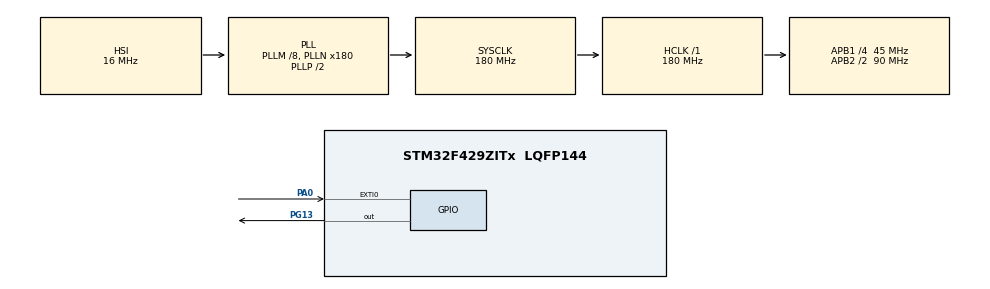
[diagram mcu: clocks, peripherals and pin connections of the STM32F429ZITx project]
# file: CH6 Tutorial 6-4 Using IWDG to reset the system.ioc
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IWDG.Prescaler=IWDG_PRESCALER_32
IWDG.Reload=4000-1
Mcu.Family=STM32F4
Mcu.Name=STM32F429ZITx
Mcu.Package=LQFP144
NVIC.EXTI0_IRQn=true\:1\:0\:true\:false\:true\:true\:true\:true
NVIC.PriorityGroup=NVIC_PRIORITYGROUP_1
NVIC.TIM1_UP_TIM10_IRQn=true\:1\:0\:true\:false\:true\:true\:true\:true
PA0/WKUP.GPIO_ModeDefaultEXTI=GPIO_MODE_IT_RISING
PA0/WKUP.Signal=GPXTI0
PG13.Signal=GPIO_Output
ProjectManager.HeapSize=0x200
ProjectManager.StackSize=0x400
ProjectManager.TargetToolchain=STM32CubeIDE
RCC.48MHZClocksFreq_Value=51428571.428571425
RCC.AHBFreq_Value=180000000
RCC.APB1CLKDivider=RCC_HCLK_DIV4
RCC.APB1Freq_Value=45000000
RCC.APB1TimFreq_Value=90000000
RCC.APB2CLKDivider=RCC_HCLK_DIV2
RCC.APB2Freq_Value=90000000
RCC.APB2TimFreq_Value=180000000
RCC.CortexFreq_Value=180000000
RCC.HCLKFreq_Value=180000000
RCC.HSE_VALUE=8000000
RCC.HSI_VALUE=16000000
RCC.LSE_VALUE=32768
RCC.PLLM=8
RCC.PLLN=180
RCC.PLLQ=7
RCC.SYSCLKFreq_VALUE=180000000
RCC.SYSCLKSource=RCC_SYSCLKSOURCE_PLLCLK
RCC.VCOOutputFreq_Value=360000000
TIM1.Period=50000-1
TIM1.Prescaler=3600-1
VP_IWDG_VS_IWDG.Mode=IWDG_Activate
VP_TIM1_VS_ClockSourceINT.Mode=Internal
board=STM32F429I-DISC1

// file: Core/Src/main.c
/* USER CODE BEGIN Header */
/**
  ******************************************************************************
  * @file           : main.c
  * @brief          : Main program body
  ******************************************************************************
  * @attention
  *
  * Copyright (c) 2023 STMicroelectronics.
  * All rights reserved.
  *
  * This software is licensed under terms that can be found in the LICENSE file
  * in the root directory of this software component.
  * If no LICENSE file comes with this software, it is provided AS-IS.
  *
  ******************************************************************************
  */
	/***************************** Tutorial Tags ******************************
	 Independent Watchdog (IWDG)Timer
	 GPIO Digital output
	 GPIO Interrupt
	 **************************************************************************/

	/* 6.4.1 Timer Usage C Language: ******************************************
	* Tutorial 6-4: Using IWDG to reset the system, in C language
	*

    Use the IWDG to reset the CPU when the code goes into an infinite loop

	So, in this tutorial we toggle the green led every 1s using timer interrupt.
	We also set IWDG to start with 4s timeout. The IWDG is refreshed every time
	the green led is toggled. When the user button is pressed, a GPIO interrupt is
	generated and the code goes into an infinite loop. After 4 seconds lapses, IWDG
	resets CPU and the code goes back to toggling the green led.
	***************************************************************************/
/* USER CODE END Header */
#include "main.h"

IWDG_HandleTypeDef hiwdg;

TIM_HandleTypeDef htim1;

void SystemClock_Config(void);
static void MX_GPIO_Init(void);
static void MX_IWDG_Init(void);
static void MX_TIM1_Init(void);

int main(void)
{

  /* MCU Configuration--------------------------------------------------------*/

  /* Reset of all peripherals, Initializes the Flash interface and the Systick. */
  HAL_Init();

  /* Configure the system clock */
  SystemClock_Config();

  /* Initialize all configured peripherals */
  MX_GPIO_Init();
  MX_IWDG_Init();
  MX_TIM1_Init();
  /* USER CODE BEGIN 2 */
  HAL_TIM_Base_Start_IT(&htim1);

  /* USER CODE END 2 */

  /* Infinite loop */
  while (1)
  {

  }
}

void SystemClock_Config(void)
{
  RCC_OscInitTypeDef RCC_OscInitStruct = {0};
  RCC_ClkInitTypeDef RCC_ClkInitStruct = {0};

  /** Configure the main internal regulator output voltage
  */
  __HAL_RCC_PWR_CLK_ENABLE();
  __HAL_PWR_VOLTAGESCALING_CONFIG(PWR_REGULATOR_VOLTAGE_SCALE1);

  /** Initializes the RCC Oscillators according to the specified parameters
  * in the RCC_OscInitTypeDef structure.
  */
  RCC_OscInitStruct.OscillatorType = RCC_OSCILLATORTYPE_HSI|RCC_OSCILLATORTYPE_LSI;
  RCC_OscInitStruct.HSIState = RCC_HSI_ON;
  RCC_OscInitStruct.HSICalibrationValue = RCC_HSICALIBRATION_DEFAULT;
  RCC_OscInitStruct.LSIState = RCC_LSI_ON;
  RCC_OscInitStruct.PLL.PLLState = RCC_PLL_ON;
  RCC_OscInitStruct.PLL.PLLSource = RCC_PLLSOURCE_HSI;
  RCC_OscInitStruct.PLL.PLLM = 8;
  RCC_OscInitStruct.PLL.PLLN = 180;
  RCC_OscInitStruct.PLL.PLLP = RCC_PLLP_DIV2;
  RCC_OscInitStruct.PLL.PLLQ = 7;
  if (HAL_RCC_OscConfig(&RCC_OscInitStruct) != HAL_OK)
  {
    Error_Handler();
  }

  /** Activate the Over-Drive mode
  */
  if (HAL_PWREx_EnableOverDrive() != HAL_OK)
  {
    Error_Handler();
  }

  /** Initializes the CPU, AHB and APB buses clocks
  */
  RCC_ClkInitStruct.ClockType = RCC_CLOCKTYPE_HCLK|RCC_CLOCKTYPE_SYSCLK
                              |RCC_CLOCKTYPE_PCLK1|RCC_CLOCKTYPE_PCLK2;
  RCC_ClkInitStruct.SYSCLKSource = RCC_SYSCLKSOURCE_PLLCLK;
  RCC_ClkInitStruct.AHBCLKDivider = RCC_SYSCLK_DIV1;
  RCC_ClkInitStruct.APB1CLKDivider = RCC_HCLK_DIV4;
  RCC_ClkInitStruct.APB2CLKDivider = RCC_HCLK_DIV2;

  if (HAL_RCC_ClockConfig(&RCC_ClkInitStruct, FLASH_LATENCY_5) != HAL_OK)
  {
    Error_Handler();
  }
}

static void MX_IWDG_Init(void)
{

  hiwdg.Instance = IWDG;
  hiwdg.Init.Prescaler = IWDG_PRESCALER_32;
  hiwdg.Init.Reload = 4000-1;
  if (HAL_IWDG_Init(&hiwdg) != HAL_OK)
  {
    Error_Handler();
  }

}

static void MX_TIM1_Init(void)
{

  TIM_ClockConfigTypeDef sClockSourceConfig = {0};
  TIM_MasterConfigTypeDef sMasterConfig = {0};

  htim1.Instance = TIM1;
  htim1.Init.Prescaler = 3600-1;
  htim1.Init.CounterMode = TIM_COUNTERMODE_UP;
  htim1.Init.Period = 50000-1;
  htim1.Init.ClockDivision = TIM_CLOCKDIVISION_DIV1;
  htim1.Init.RepetitionCounter = 0;
  htim1.Init.AutoReloadPreload = TIM_AUTORELOAD_PRELOAD_DISABLE;
  if (HAL_TIM_Base_Init(&htim1) != HAL_OK)
  {
    Error_Handler();
  }
  sClockSourceConfig.ClockSource = TIM_CLOCKSOURCE_INTERNAL;
  if (HAL_TIM_ConfigClockSource(&htim1, &sClockSourceConfig) != HAL_OK)
  {
    Error_Handler();
  }
  sMasterConfig.MasterOutputTrigger = TIM_TRGO_RESET;
  sMasterConfig.MasterSlaveMode = TIM_MASTERSLAVEMODE_DISABLE;
  if (HAL_TIMEx_MasterConfigSynchronization(&htim1, &sMasterConfig) != HAL_OK)
  {
    Error_Handler();
  }

}

static void MX_GPIO_Init(void)
{
  GPIO_InitTypeDef GPIO_InitStruct = {0};

  /* GPIO Ports Clock Enable */
  __HAL_RCC_GPIOA_CLK_ENABLE();
  __HAL_RCC_GPIOG_CLK_ENABLE();

  /*Configure GPIO pin Output Level */
  HAL_GPIO_WritePin(GPIOG, GPIO_PIN_13, GPIO_PIN_RESET);

  /*Configure GPIO pin : PA0 */
  GPIO_InitStruct.Pin = GPIO_PIN_0;
  GPIO_InitStruct.Mode = GPIO_MODE_IT_RISING;
  GPIO_InitStruct.Pull = GPIO_NOPULL;
  HAL_GPIO_Init(GPIOA, &GPIO_InitStruct);

  /*Configure GPIO pin : PG13 */
  GPIO_InitStruct.Pin = GPIO_PIN_13;
  GPIO_InitStruct.Mode = GPIO_MODE_OUTPUT_PP;
  GPIO_InitStruct.Pull = GPIO_NOPULL;
  GPIO_InitStruct.Speed = GPIO_SPEED_FREQ_LOW;
  HAL_GPIO_Init(GPIOG, &GPIO_InitStruct);

  /* EXTI interrupt init*/
  HAL_NVIC_SetPriority(EXTI0_IRQn, 1, 0);
  HAL_NVIC_EnableIRQ(EXTI0_IRQn);

}

/* USER CODE BEGIN 4 */
void HAL_TIM_PeriodElapsedCallback(TIM_HandleTypeDef *htim){
	//printf("Reload register value %lu\r\t\%lu\r\n ", IWDG->RLR, hiwdg.Instance->RLR);
	//WRITE_REG((__HANDLE__)->Instance->KR, IWDG_KEY_RELOAD)
	if(htim == &htim1){
		HAL_GPIO_TogglePin(GPIOG, GPIO_PIN_13);
		HAL_IWDG_Refresh(&hiwdg);

	}

}
void HAL_GPIO_EXTI_Callback(uint16_t GPIO_Pin){
	if(GPIO_Pin == GPIO_PIN_0){
		while(1);
	}

}

// HAL_IWDG_Refresh(IWDG_HandleTypeDef *hiwdg)
/* USER CODE END 4 */

void Error_Handler(void)
{
  __disable_irq();
  while (1)
  {
  }
}
